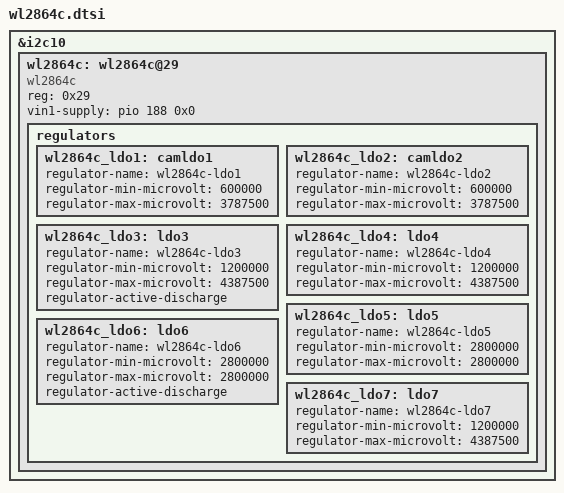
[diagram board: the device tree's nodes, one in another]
// SPDX-License-Identifier: GPL-2.0
//
// Copyright (c) 2021 MediaTek Inc.
&i2c10 {
	wl2864c: wl2864c@29 {
		status = "ok";
		compatible = "wl2864c";
		reg = <0x29>;
		vin1-supply = <&pio 188 0x0>;
		regulators {
			wl2864c_ldo1: camldo1 {
				regulator-name = "wl2864c-ldo1";
				regulator-min-microvolt = <600000>;
				regulator-max-microvolt = <3787500>;

			};
			wl2864c_ldo2: camldo2 {
				regulator-name = "wl2864c-ldo2";
				regulator-min-microvolt = <600000>;
				regulator-max-microvolt = <3787500>;

			};
			wl2864c_ldo3: ldo3 {
				regulator-name = "wl2864c-ldo3";
				regulator-min-microvolt = <1200000>;
				regulator-max-microvolt = <4387500>;
				regulator-active-discharge;
			};
			wl2864c_ldo4: ldo4 {
				regulator-name = "wl2864c-ldo4";
				regulator-min-microvolt = <1200000>;
				regulator-max-microvolt = <4387500>;
			};
			wl2864c_ldo5: ldo5 {
				regulator-name = "wl2864c-ldo5";
				regulator-min-microvolt = <2800000>;
				regulator-max-microvolt = <2800000>;
			};
			wl2864c_ldo6: ldo6 {
				regulator-name = "wl2864c-ldo6";
				regulator-min-microvolt = <2800000>;
				regulator-max-microvolt = <2800000>;
				regulator-active-discharge;
			};
			wl2864c_ldo7: ldo7 {
				regulator-name = "wl2864c-ldo7";
				regulator-min-microvolt = <1200000>;
				regulator-max-microvolt = <4387500>;
			};
		};
	};
};

